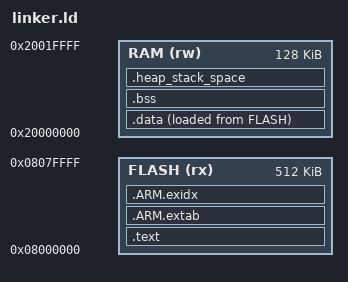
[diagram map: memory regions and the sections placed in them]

ENTRY(Reset_Handler)

_estack = ORIGIN(RAM) + LENGTH(RAM);

_Min_Heap_Size = 0x200;
_Min_Stack_Size = 0x400;

MEMORY {
    FLASH (rx) : ORIGIN = 0x08000000, LENGTH = 512K
    RAM   (rw) : ORIGIN = 0x20000000, LENGTH = 128K
}

SECTIONS {
    .text : {
        . = ALIGN(4);
        KEEP(*(.isr_vector))
        *(.text .text.* .gnu.linkonce.t.*)
        *(.rodata .rodata.* .gnu.linkonce.r.*)
        . = ALIGN(4);
        _etext = .;

        . = ALIGN(4);
        KEEP(*(.init))
        . = ALIGN(4);
        __preinit_array_start = .;
        KEEP (*(.preinit_array))
        __preinit_array_end = .;

        . = ALIGN(4);
        __init_array_start = .;
        KEEP (*(SORT(.init_array.*)))
        KEEP (*(.init_array))
        __init_array_end = .;

        . = ALIGN(4);
        KEEP(*(.fini))
        . = ALIGN(4);
        __fini_array_start = .;
        KEEP (*(.fini_array))
        KEEP (*(SORT(.fini_array.*)))
        __fini_array_end = .;

        . = ALIGN(4);
        KEEP (*crtbegin.o(.ctors))
        KEEP (*(EXCLUDE_FILE (*crtend.o) .ctors))
        KEEP (*(SORT(.ctors.*)))
        KEEP (*crtend.o(.ctors))

        . = ALIGN(4);
        KEEP (*crtbegin.o(.dtors))
        KEEP (*(EXCLUDE_FILE (*crtend.o) .dtors))
        KEEP (*(SORT(.dtors.*)))
        KEEP (*crtend.o(.dtors))
        . = ALIGN(4);
        _efixed = .;
    } > FLASH

    .ARM.extab : {
        . = ALIGN(4);
        *(.ARM.extab* .gnu.linkonce.armextab.*)
    } > FLASH

    .ARM.exidx : {
        . = ALIGN(4);
        PROVIDE (__exidx_start = .);
        *(.ARM.exidx* .gnu.linkonce.armexidx.*)
        . = ALIGN(4);
        PROVIDE (__exidx_end = .);
    } > FLASH

    _sidata = LOADADDR(.data);

    .data : {
        . = ALIGN(4);
        _sdata = .;
        *(.data .data.*)
        . = ALIGN(4);
        _edata = .;
    } > RAM AT > FLASH

    .bss (NOLOAD) : {
        . = ALIGN(4);
        _sbss = .;
        *(.bss .bss.*)
        *(COMMON)
        . = ALIGN(4);
        _ebss = .;
    } > RAM

    .heap_stack_space (NOLOAD) : {
        . = ALIGN(8);
        PROVIDE ( end = . );
        PROVIDE ( _end = . );
        . = . + _Min_Heap_Size;
        . = . + _Min_Stack_Size;
        . = ALIGN(8);
    } > RAM
}
